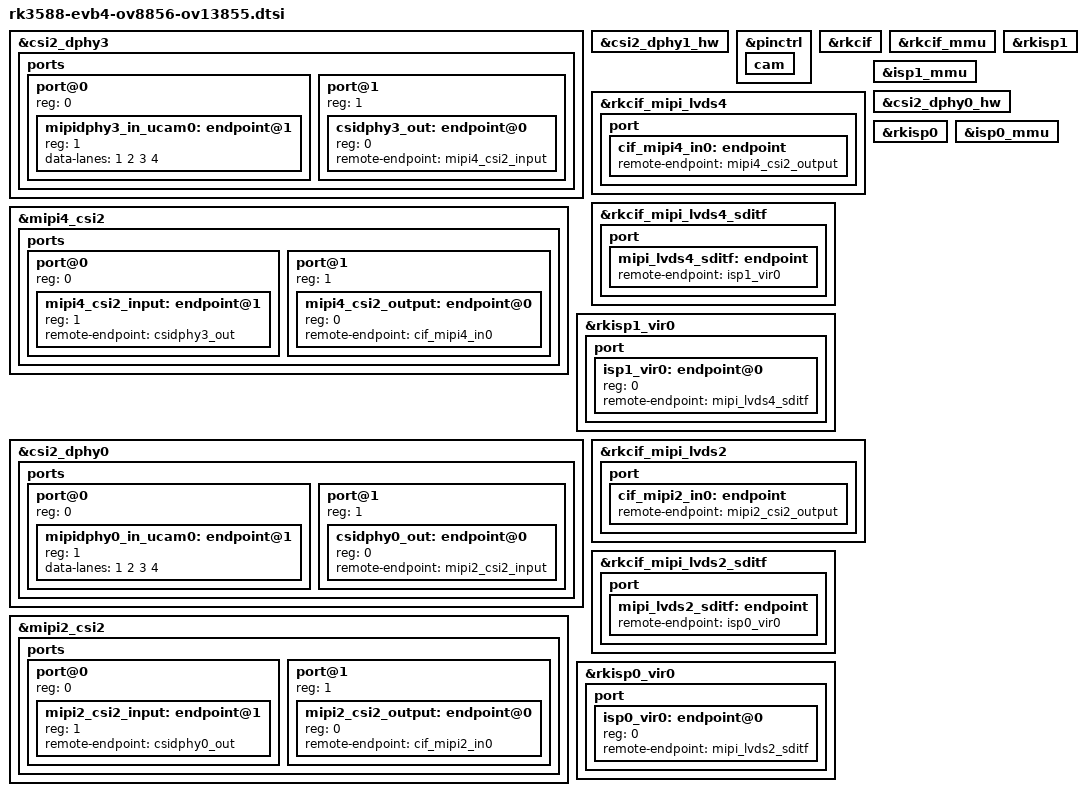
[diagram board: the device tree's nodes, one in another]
&csi2_dphy3 {
	status = "okay";

	ports {
		#address-cells = <1>;
		#size-cells = <0>;
		port@0 {
			reg = <0>;
			#address-cells = <1>;
			#size-cells = <0>;

			mipidphy3_in_ucam0: endpoint@1 {
				reg = <1>;
				// remote-endpoint = <&ov13855_out1>;
				data-lanes = <1 2 3 4>;
			};
		};
		port@1 {
			reg = <1>;
			#address-cells = <1>;
			#size-cells = <0>;

			csidphy3_out: endpoint@0 {
				reg = <0>;
				remote-endpoint = <&mipi4_csi2_input>;
			};
		};
	};
};

&csi2_dphy1_hw {
	status = "okay";
};

/*
&i2c4 {
	status = "okay";
	pinctrl-0 = <&i2c4m3_xfer>;

        dw9763: dw9763@c {
               compatible = "dongwoon,dw9763";
               status = "okay";
               reg = <0x0c>;
               rockchip,vcm-start-current = <0>;
               rockchip,vcm-rated-current = <100>;
               rockchip,vcm-step-mode = <4>;
	       rockchip,vcm-adcanced-mode = <1>;
               rockchip,camera-module-index = <0>;
               rockchip,camera-module-facing = "back";
        };

	ov13855: ov13855@10 {
		compatible = "ovti,ov13855";
		status = "okay";
		reg = <0x10>;
		clocks = <&cru CLK_MIPI_CAMARAOUT_M2>;
		clock-names = "xvclk";
		pinctrl-names = "default";
		pinctrl-0 = <&mipim0_camera2_clk>;
		power-domains = <&power RK3588_PD_VI>;
		//power-gpios = <&gpio1 RK_PA4 GPIO_ACTIVE_HIGH>;
		reset-gpios = <&gpio1 RK_PB3 GPIO_ACTIVE_HIGH>;
		pwdn-gpios = <&gpio1 RK_PB5 GPIO_ACTIVE_HIGH>;
		//lf-gpios = <&aw_gpio1 0 GPIO_ACTIVE_HIGH>;
		//iovdd-gpios = <&aw_gpio1 1 GPIO_ACTIVE_HIGH>;
		//vaf-gpios = <&aw_gpio1 2 GPIO_ACTIVE_HIGH>;
		//avdd-gpios = <&aw_gpio1 3 GPIO_ACTIVE_HIGH>;
		//dvdd-gpios = <&aw_gpio1 4 GPIO_ACTIVE_HIGH>;
		rockchip,camera-module-index = <0>;
		rockchip,camera-module-facing = "back";
		rockchip,camera-module-name = "CMK-OT2016-FV1";
		rockchip,camera-module-lens-name = "default";
		lens-focus = <&dw9763>;
		flash-leds = <&flash_rgb13h>;
		port {
			ov13855_out1: endpoint {
				remote-endpoint = <&mipidphy3_in_ucam0>;
				data-lanes = <1 2 3 4>;
			};
		};
	};
};
*/

&mipi4_csi2 {
	status = "okay";

	ports {
		#address-cells = <1>;
		#size-cells = <0>;

		port@0 {
			reg = <0>;
			#address-cells = <1>;
			#size-cells = <0>;

			mipi4_csi2_input: endpoint@1 {
				reg = <1>;
				remote-endpoint = <&csidphy3_out>;
			};
		};

		port@1 {
			reg = <1>;
			#address-cells = <1>;
			#size-cells = <0>;

			mipi4_csi2_output: endpoint@0 {
				reg = <0>;
				remote-endpoint = <&cif_mipi4_in0>;
			};
		};
	};
};

&pinctrl {
	cam {
	/*
		mipidphy0_pwr: mipidphy0-pwr {
			rockchip,pins =
				<1 RK_PB2 RK_FUNC_GPIO &pcfg_pull_none>;
		};
	*/
	};
};

&rkcif {
	status = "okay";
};

&rkcif_mipi_lvds4 {
	status = "okay";

	port {
		cif_mipi4_in0: endpoint {
			remote-endpoint = <&mipi4_csi2_output>;
		};
	};
};

&rkcif_mipi_lvds4_sditf {
	status = "okay";

	port {
		mipi_lvds4_sditf: endpoint {
			remote-endpoint = <&isp1_vir0>;
		};
	};
};

&rkcif_mmu {
	status = "okay";
};

&rkisp1 {
	status = "okay";
};

&isp1_mmu {
	status = "okay";
};

&rkisp1_vir0 {
	status = "okay";

	port {
		#address-cells = <1>;
		#size-cells = <0>;

		isp1_vir0: endpoint@0 {
			reg = <0>;
			remote-endpoint = <&mipi_lvds4_sditf>;
		};
	};
};

&csi2_dphy0 {
	status = "okay";

	ports {
		#address-cells = <1>;
		#size-cells = <0>;
		port@0 {
			reg = <0>;
			#address-cells = <1>;
			#size-cells = <0>;

			mipidphy0_in_ucam0: endpoint@1 {
				reg = <1>;
				//remote-endpoint = <&ov8856_out0>;
				data-lanes = <1 2 3 4>;
			};
		};
		port@1 {
			reg = <1>;
			#address-cells = <1>;
			#size-cells = <0>;

			csidphy0_out: endpoint@0 {
				reg = <0>;
				remote-endpoint = <&mipi2_csi2_input>;
			};
		};
	};
};

&csi2_dphy0_hw {
	status = "okay";
};

/*
&i2c4 {
	status = "okay";
	pinctrl-0 = <&i2c4m3_xfer>;

	ov8856: ov8856@36 {
		compatible = "ovti,ov8856";
		status = "okay";
		reg = <0x36>;
		clocks = <&cru CLK_MIPI_CAMARAOUT_M1>;
		clock-names = "xvclk";
		pinctrl-names = "default";
		pinctrl-0 = <&mipim0_camera1_clk>;
		power-domains = <&power RK3588_PD_VI>;
		//power-gpios = <&gpio1 RK_PA4 GPIO_ACTIVE_HIGH>;
		reset-gpios = <&gpio1 RK_PB2 GPIO_ACTIVE_HIGH>;
		pwdn-gpios = <&gpio1 RK_PB4 GPIO_ACTIVE_HIGH>;
		//lf-gpios = <&aw_gpio1 0 GPIO_ACTIVE_HIGH>;
		//iovdd-gpios = <&aw_gpio1 1 GPIO_ACTIVE_HIGH>;
		//vaf-gpios = <&aw_gpio1 2 GPIO_ACTIVE_HIGH>;
		//avdd-gpios = <&aw_gpio1 3 GPIO_ACTIVE_HIGH>;
		//dvdd-gpios = <&aw_gpio1 4 GPIO_ACTIVE_HIGH>;
		rockchip,camera-module-index = <1>;
		rockchip,camera-module-facing = "front";
		rockchip,camera-module-name = "HZGA06";
		rockchip,camera-module-lens-name = "ZE0082C1";
		port {
			ov8856_out0: endpoint {
				remote-endpoint = <&mipidphy0_in_ucam0>;
				data-lanes = <1 2 3 4>;
			};
		};
	};
};
*/

&mipi2_csi2 {
	status = "okay";

	ports {
		#address-cells = <1>;
		#size-cells = <0>;

		port@0 {
			reg = <0>;
			#address-cells = <1>;
			#size-cells = <0>;

			mipi2_csi2_input: endpoint@1 {
				reg = <1>;
				remote-endpoint = <&csidphy0_out>;
			};
		};

		port@1 {
			reg = <1>;
			#address-cells = <1>;
			#size-cells = <0>;

			mipi2_csi2_output: endpoint@0 {
				reg = <0>;
				remote-endpoint = <&cif_mipi2_in0>;
			};
		};
	};
};

&pinctrl {
	cam {
	/*
		mipidphy0_pwr: mipidphy0-pwr {
			rockchip,pins =
				<1 RK_PB2 RK_FUNC_GPIO &pcfg_pull_none>;
		};
	*/
	};
};

&rkcif {
	status = "okay";
};

&rkcif_mipi_lvds2 {
	status = "okay";

	port {
		cif_mipi2_in0: endpoint {
			remote-endpoint = <&mipi2_csi2_output>;
		};
	};
};

&rkcif_mipi_lvds2_sditf {
	status = "okay";

	port {
		mipi_lvds2_sditf: endpoint {
			remote-endpoint = <&isp0_vir0>;
		};
	};
};

&rkcif_mmu {
	status = "okay";
};

&rkisp0 {
	status = "okay";
};

&isp0_mmu {
	status = "okay";
};

&rkisp0_vir0 {
	status = "okay";

	port {
		#address-cells = <1>;
		#size-cells = <0>;

		isp0_vir0: endpoint@0 {
			reg = <0>;
			remote-endpoint = <&mipi_lvds2_sditf>;
		};
	};
};
